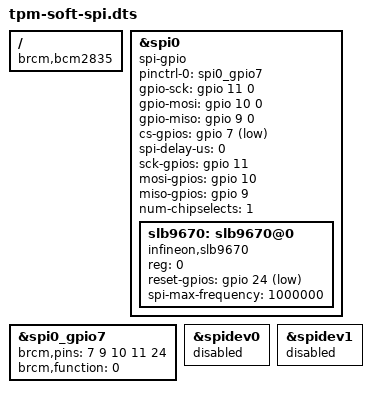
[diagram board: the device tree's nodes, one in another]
/*
 * Trusted Platform overlay: Infineon SLB9670 TPM 2.0 on SPI0 CE1, driven as
 * a GPIO bit-banged bus so that U-Boot (which has no BCM2835 SPI controller
 * driver) and Linux (spi-gpio + tpm_tis_spi) see the same device.
 *
 * Pins: SCLK GPIO11, MOSI GPIO10, MISO GPIO9, CE1 GPIO7 (active low),
 * optional reset GPIO24 (Iridium 9670 boards; unconnected on LetsTrust).
 * Replaces the kernel's tpm-slb9670 overlay, which enables the hardware
 * SPI0 controller U-Boot cannot use.
 */

/dts-v1/;
/plugin/;

/ {
	compatible = "brcm,bcm2835";

	fragment@0 {
		target = <&spi0>;
		__overlay__ {
			compatible = "spi-gpio";
			pinctrl-names = "default";
			pinctrl-0 = <&spi0_gpio7>;
			/* U-Boot soft_spi property names */
			gpio-sck = <&gpio 11 0>;
			gpio-mosi = <&gpio 10 0>;
			gpio-miso = <&gpio 9 0>;
			cs-gpios = <&gpio 7 1>;
			spi-delay-us = <0>;
			/* Linux spi-gpio property names */
			sck-gpios = <&gpio 11 0>;
			mosi-gpios = <&gpio 10 0>;
			miso-gpios = <&gpio 9 0>;
			num-chipselects = <1>;
			#address-cells = <1>;
			#size-cells = <0>;
			status = "okay";

			slb9670: slb9670@0 {
				compatible = "infineon,slb9670", "tcg,tpm_tis-spi";
				reg = <0>;
				reset-gpios = <&gpio 24 1>;
				spi-max-frequency = <1000000>;
				#address-cells = <1>;
				#size-cells = <0>;
				status = "okay";
			};
		};
	};

	fragment@1 {
		target = <&spi0_gpio7>;
		__overlay__ {
			brcm,pins = <7 9 10 11 24>;
			brcm,function = <0>;
		};
	};

	fragment@2 {
		target = <&spidev0>;
		__overlay__ {
			status = "disabled";
		};
	};

	fragment@3 {
		target = <&spidev1>;
		__overlay__ {
			status = "disabled";
		};
	};
};
